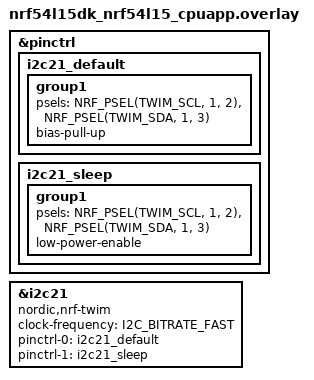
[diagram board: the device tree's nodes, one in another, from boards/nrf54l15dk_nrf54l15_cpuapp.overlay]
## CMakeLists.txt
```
# Smart-ring firmware for the Nordic nRF54L15 DK (cpuapp).
cmake_minimum_required(VERSION 3.20.0)

find_package(Zephyr REQUIRED HINTS $ENV{ZEPHYR_BASE})
project(smart_ring)

# Portable sensor-manager core, compiled unmodified into the app, plus its
# Zephyr port. SM_PORT_ZEPHYR selects the k_spinlock / k_uptime backing.
set(CORE_DIR ${CMAKE_CURRENT_SOURCE_DIR}/../../src)

target_sources(app PRIVATE
  src/main.c
  src/sensors.c
  src/ble.c
  ${CORE_DIR}/sensor_manager.c
  ${CORE_DIR}/sm_ringbuf.c
  ${CORE_DIR}/port/sm_port_zephyr.c
)

# ble_batch is only needed by the BLE notify path (enabled via ble.conf).
if(CONFIG_BT)
  target_sources(app PRIVATE ${CORE_DIR}/ble_batch.c)
endif()

target_include_directories(app PRIVATE ${CORE_DIR})
target_compile_definitions(app PRIVATE SM_PORT_ZEPHYR)
```

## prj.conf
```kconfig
# Smart-ring Zephyr app configuration.
CONFIG_PRINTK=y

# I2C sensor bus (TWIM21). The app uses the raw I2C API directly.
CONFIG_I2C=y
```

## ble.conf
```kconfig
# DK-only BLE build. Enables the Ring Data Service (src/ble.c) on top of the
# sensor pipeline. Uses upstream Zephyr's software Link-Layer controller, so it
# needs no nRF Connect SDK / SoftDevice blobs.
#
# Build with:
#   west build -b nrf54l15dk/nrf54l15/cpuapp . -- -DEXTRA_CONF_FILE=ble.conf
#
# Not runnable in LabWired: the nRF54L radio is not modelled.
CONFIG_BT=y
CONFIG_BT_PERIPHERAL=y
CONFIG_BT_DEVICE_NAME="SmartRing"
```

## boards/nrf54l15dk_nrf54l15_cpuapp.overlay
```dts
/*
 * Smart-ring sensor bus. The four sensors share TWIM21 (Zephyr node i2c21),
 * which is the instance LabWired's smart-ring system models as "twi21":
 *
 *   BMI270  IMU     0x68     MAX30102 PPG     0x57
 *   TMP117  temp    0x48     DRV2605  haptic  0x5A
 *
 * Addresses live in sensors.c (the app uses the raw I2C API against the bus
 * controller, not per-sensor drivers), so this overlay only has to bring the
 * bus up and give it pins.
 */

&pinctrl {
	i2c21_default: i2c21_default {
		group1 {
			psels = <NRF_PSEL(TWIM_SCL, 1, 2)>,
				<NRF_PSEL(TWIM_SDA, 1, 3)>;
			bias-pull-up;
		};
	};

	i2c21_sleep: i2c21_sleep {
		group1 {
			psels = <NRF_PSEL(TWIM_SCL, 1, 2)>,
				<NRF_PSEL(TWIM_SDA, 1, 3)>;
			low-power-enable;
		};
	};
};

&i2c21 {
	compatible = "nordic,nrf-twim";
	status = "okay";
	clock-frequency = <I2C_BITRATE_FAST>;
	pinctrl-0 = <&i2c21_default>;
	pinctrl-1 = <&i2c21_sleep>;
	pinctrl-names = "default", "sleep";
};
```

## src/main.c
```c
/*
 * main.c - smart-ring app entry point. Initialises the sensors and the
 * portable sensor-manager core, then runs the acquisition loop: a 20 ms timer
 * paces reads of the BMI270 (50 Hz) and TMP117 (1 Hz) into the manager, and
 * once a second the manager's pushed/dropped/buffered stats are printed.
 */
#include <zephyr/kernel.h>
#include <zephyr/version.h>

#include "sensors.h"
#include "sensor_manager.h"
#include "ble.h"

/* Acquisition tick. The IMU runs at 50 Hz, so one tick == one IMU period; the
 * manager's rate controllers derive the 1 Hz temperature cadence from it. */
#define TICK_PERIOD  K_MSEC(20)
#define STATS_PERIOD_US 1000000ULL

/* The timer only marks time; the blocking I2C reads happen in the loop below
 * (thread context), woken by this semaphore. */
static K_SEM_DEFINE(tick_sem, 0, 1);

static void tick_expiry(struct k_timer *timer)
{
	ARG_UNUSED(timer);
	k_sem_give(&tick_sem);
}

static K_TIMER_DEFINE(tick_timer, tick_expiry, NULL);

static void print_stats(sensor_manager_t *mgr)
{
	sm_stats_t s;

	sm_get_stats(mgr, &s);
	printk("stats: imu pushed=%u dropped=%u buffered=%u/%u missed=%u | "
	       "temp pushed=%u dropped=%u buffered=%u/%u missed=%u\n",
	       s.imu.pushed, s.imu.dropped, s.imu.count, s.imu.capacity,
	       s.imu_missed_deadlines, s.temp.pushed, s.temp.dropped, s.temp.count,
	       s.temp.capacity, s.temp_missed_deadlines);
}

int main(void)
{
	printk("\n=== smart-ring nRF54L15 (Zephyr %s) ===\n", KERNEL_VERSION_STRING);

	if (!sensors_init()) {
		printk("sensor bring-up failed; halting\n");
		return 0;
	}

	sensor_manager_t mgr;

	if (sm_init(&mgr, sm_time_now_us()) != SM_OK) {
		printk("sensor-manager init failed; halting\n");
		return 0;
	}

	ble_start(); /* advertises the Ring Data Service on the DK; no-op without CONFIG_BT */

	k_timer_start(&tick_timer, TICK_PERIOD, TICK_PERIOD);

	uint64_t last_stats_us = sm_time_now_us();

	for (;;) {
		k_sem_take(&tick_sem, K_FOREVER);

		uint64_t now_us = sm_time_now_us();

		if (sm_rate_poll(&mgr.imu_rate, now_us)) {
			int16_t accel[3], gyro[3];

			if (sensors_read_imu(accel, gyro) == 0) {
				sm_submit_imu(&mgr, accel, gyro, now_us);
			}
		}

		if (sm_rate_poll(&mgr.temp_rate, now_us)) {
			int32_t milli_celsius;

			if (sensors_read_temp(&milli_celsius) == 0) {
				sm_submit_temp(&mgr, milli_celsius, now_us);
			}
		}

		if (now_us - last_stats_us >= STATS_PERIOD_US) {
			print_stats(&mgr);
			ble_notify_imu(&mgr); /* drain a batch to the phone; no-op without CONFIG_BT */
			last_stats_us = now_us;
		}
	}

	return 0;
}
```

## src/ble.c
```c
/*
 * ble.c - Ring Data Service (IMU batch notifications). See ble.h.
 */
#include "ble.h"

#if defined(CONFIG_BT)

#include <zephyr/bluetooth/bluetooth.h>
#include <zephyr/bluetooth/conn.h>
#include <zephyr/bluetooth/gatt.h>
#include <zephyr/bluetooth/uuid.h>
#include <zephyr/kernel.h>

#include "ble_batch.h"
#include "sensor_manager.h"

/* Ring Data Service, random 128-bit base:
 *   service        7e9d0001-... , IMU-batch characteristic 7e9d0002-...
 */
#define RDS_UUID_SERVICE                                                                       \
	BT_UUID_128_ENCODE(0x7e9d0001, 0xc4b3, 0x4f2a, 0x9a10, 0x0011223344ff)
#define RDS_UUID_IMU_BATCH                                                                     \
	BT_UUID_128_ENCODE(0x7e9d0002, 0xc4b3, 0x4f2a, 0x9a10, 0x0011223344ff)

static const struct bt_uuid_128 rds_service = BT_UUID_INIT_128(RDS_UUID_SERVICE);
static const struct bt_uuid_128 rds_imu_batch = BT_UUID_INIT_128(RDS_UUID_IMU_BATCH);

static struct bt_conn *current_conn;
static bool notify_enabled;

static void imu_ccc_changed(const struct bt_gatt_attr *attr, uint16_t value)
{
	ARG_UNUSED(attr);
	notify_enabled = (value == BT_GATT_CCC_NOTIFY);
}

/* Notify-only characteristic: the phone subscribes, the ring pushes batches. */
BT_GATT_SERVICE_DEFINE(rds_svc,
	BT_GATT_PRIMARY_SERVICE(&rds_service),
	BT_GATT_CHARACTERISTIC(&rds_imu_batch.uuid, BT_GATT_CHRC_NOTIFY, BT_GATT_PERM_NONE,
			       NULL, NULL, NULL),
	BT_GATT_CCC(imu_ccc_changed, BT_GATT_PERM_READ | BT_GATT_PERM_WRITE));

/* The notify attribute is the characteristic value, index 2 in the table. */
#define IMU_VALUE_ATTR (&rds_svc.attrs[2])

static const struct bt_data adv[] = {
	BT_DATA_BYTES(BT_DATA_FLAGS, BT_LE_AD_GENERAL | BT_LE_AD_NO_BREDR),
	BT_DATA(BT_DATA_NAME_COMPLETE, CONFIG_BT_DEVICE_NAME, sizeof(CONFIG_BT_DEVICE_NAME) - 1),
};

static void connected(struct bt_conn *conn, uint8_t err)
{
	if (err == 0) {
		current_conn = bt_conn_ref(conn);
	}
	printk("ble: connected (err %u)\n", err);
}

static void disconnected(struct bt_conn *conn, uint8_t reason)
{
	ARG_UNUSED(conn);
	notify_enabled = false;
	if (current_conn) {
		bt_conn_unref(current_conn);
		current_conn = NULL;
	}
	printk("ble: disconnected (reason %u)\n", reason);
}

BT_CONN_CB_DEFINE(conn_cb) = {
	.connected = connected,
	.disconnected = disconnected,
};

int ble_start(void)
{
	int err = bt_enable(NULL);

	if (err) {
		printk("ble: bt_enable failed (%d)\n", err);
		return err;
	}
	err = bt_le_adv_start(BT_LE_ADV_CONN_FAST_1, adv, ARRAY_SIZE(adv), NULL, 0);
	if (err) {
		printk("ble: adv start failed (%d)\n", err);
	}
	return err;
}

void ble_notify_imu(sensor_manager_t *mgr)
{
	if (!current_conn || !notify_enabled) {
		return;
	}

	sm_imu_sample_t samples[BLE_IMU_MAX_RECORDS(BLE_DEFAULT_PAYLOAD)];
	size_t n = sm_peek_imu(mgr, samples, ARRAY_SIZE(samples));

	if (n == 0) {
		return;
	}

	sm_stats_t stats;

	sm_get_stats(mgr, &stats);

	uint8_t frame[BLE_DEFAULT_PAYLOAD];
	size_t consumed = 0;
	size_t len =
		ble_batch_encode_imu(samples, n, stats.imu.dropped, frame, sizeof(frame), &consumed);

	if (len > 0 && bt_gatt_notify(current_conn, IMU_VALUE_ATTR, frame, len) == 0) {
		sm_release_imu(mgr, consumed);
	}
}

#else /* !CONFIG_BT: inert stubs so main.c needs no #ifdefs. */

int ble_start(void)
{
	return 0;
}

void ble_notify_imu(sensor_manager_t *mgr)
{
	(void)mgr;
}

#endif /* CONFIG_BT */
```

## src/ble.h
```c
/*
 * ble.h - Ring Data Service: a minimal BLE peripheral that streams IMU batches.
 *
 * Built only when CONFIG_BT is enabled (see ble.conf); otherwise the two
 * entry points below compile to no-ops so main.c needs no #ifdefs. BLE is a
 * DK-only feature: LabWired does not model the nRF54L radio, so this path is
 * exercised on real silicon, not in the simulator.
 */
#ifndef BLE_H
#define BLE_H

#include "sensor_manager.h"

/* Start advertising the Ring Data Service. No-op (returns 0) without CONFIG_BT. */
int ble_start(void);

/*
 * Drain pending IMU samples from the manager into one GATT notification,
 * encoded with ble_batch_encode_imu. Does nothing if no central is connected
 * or nothing is buffered. No-op without CONFIG_BT.
 */
void ble_notify_imu(sensor_manager_t *mgr);

#endif /* BLE_H */
```

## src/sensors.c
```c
/*
 * sensors.c - raw-I2C access to the smart-ring sensor bus (TWIM21 / i2c21).
 */
#include "sensors.h"

#include <zephyr/device.h>
#include <zephyr/drivers/i2c.h>
#include <zephyr/kernel.h>

/* 7-bit bus addresses (see the board overlay for the bus topology). */
#define ADDR_IMU    0x68 /* BMI270  */
#define ADDR_PPG    0x57 /* MAX30102 */
#define ADDR_TEMP   0x48 /* TMP117  */
#define ADDR_HAPTIC 0x5A /* DRV2605 */

/* BMI270: CHIP_ID register and its fixed value; 6-axis data burst. */
#define BMI270_REG_CHIP_ID 0x00
#define BMI270_CHIP_ID     0x24
#define BMI270_REG_PWR_CTRL 0x7D
#define BMI270_PWR_ACC_GYR  0x0E /* enable accel + gyro (+ temp) */
#define BMI270_REG_ACC_DATA 0x0C /* accel[3] then gyro[3], 12 LE bytes */
#define BMI270_DATA_LEN     12

/* TMP117: DEVICE_ID (0x0117) and the temperature result register. */
#define TMP117_REG_TEMP      0x00
#define TMP117_REG_DEVICE_ID 0x0F
#define TMP117_DEVICE_ID     0x0117
/* 7.8125 m°C per LSB == 125/16 mC. */
#define TMP117_MC_NUM 125
#define TMP117_MC_DEN 16

/* MAX30102: PART_ID register and value (PPG, probed only). */
#define MAX30102_REG_PART_ID 0xFF
#define MAX30102_PART_ID     0x15

/* DRV2605: STATUS register; the top 3 bits carry the device ID (7). */
#define DRV2605_REG_STATUS    0x00
#define DRV2605_DEVICE_ID     7
#define DRV2605_ID_SHIFT      5

static const struct device *const i2c_bus = DEVICE_DT_GET(DT_NODELABEL(i2c21));

/* Read a big-endian 16-bit register (TMP117 layout: MSB first). */
static int read_reg16_be(uint8_t addr, uint8_t reg, uint16_t *out)
{
	uint8_t buf[2];
	int rc = i2c_burst_read(i2c_bus, addr, reg, buf, sizeof(buf));

	if (rc == 0) {
		*out = ((uint16_t)buf[0] << 8) | buf[1];
	}
	return rc;
}

bool sensors_init(void)
{
	if (!device_is_ready(i2c_bus)) {
		printk("i2c bus not ready\n");
		return false;
	}

	uint8_t chip_id = 0, part_id = 0, status = 0;
	uint16_t device_id = 0;
	bool imu_ok, temp_ok, ppg_ok, haptic_ok;

	imu_ok = i2c_reg_read_byte(i2c_bus, ADDR_IMU, BMI270_REG_CHIP_ID, &chip_id) == 0 &&
		 chip_id == BMI270_CHIP_ID;
	temp_ok = read_reg16_be(ADDR_TEMP, TMP117_REG_DEVICE_ID, &device_id) == 0 &&
		  device_id == TMP117_DEVICE_ID;
	ppg_ok = i2c_reg_read_byte(i2c_bus, ADDR_PPG, MAX30102_REG_PART_ID, &part_id) == 0 &&
		 part_id == MAX30102_PART_ID;
	haptic_ok = i2c_reg_read_byte(i2c_bus, ADDR_HAPTIC, DRV2605_REG_STATUS, &status) == 0 &&
		    (status >> DRV2605_ID_SHIFT) == DRV2605_DEVICE_ID;

	printk("probe: imu(bmi270) id=0x%02x %s\n", chip_id, imu_ok ? "OK" : "FAIL");
	printk("probe: temp(tmp117) id=0x%04x %s\n", device_id, temp_ok ? "OK" : "FAIL");
	printk("probe: ppg(max30102) id=0x%02x %s\n", part_id, ppg_ok ? "OK" : "FAIL");
	printk("probe: haptic(drv2605) id=%u %s\n", status >> DRV2605_ID_SHIFT,
	       haptic_ok ? "OK" : "FAIL");

	/*
	 * Power up the IMU's accel + gyro. A real BMI270 also needs its config
	 * blob uploaded here; that DK-only step is omitted deliberately (the
	 * data registers are all the pipeline reads).
	 */
	if (imu_ok) {
		i2c_reg_write_byte(i2c_bus, ADDR_IMU, BMI270_REG_PWR_CTRL, BMI270_PWR_ACC_GYR);
	}

	return imu_ok && temp_ok;
}

int sensors_read_imu(int16_t accel[3], int16_t gyro[3])
{
	uint8_t d[BMI270_DATA_LEN];
	int rc = i2c_burst_read(i2c_bus, ADDR_IMU, BMI270_REG_ACC_DATA, d, sizeof(d));

	if (rc != 0) {
		return rc;
	}
	for (int i = 0; i < 3; i++) {
		accel[i] = (int16_t)(d[2 * i] | (d[2 * i + 1] << 8));
		gyro[i] = (int16_t)(d[6 + 2 * i] | (d[6 + 2 * i + 1] << 8));
	}
	return 0;
}

int sensors_read_temp(int32_t *milli_celsius)
{
	uint16_t raw;
	int rc = read_reg16_be(ADDR_TEMP, TMP117_REG_TEMP, &raw);

	if (rc == 0) {
		*milli_celsius = (int32_t)(int16_t)raw * TMP117_MC_NUM / TMP117_MC_DEN;
	}
	return rc;
}
```

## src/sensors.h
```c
/*
 * sensors.h - thin driver over the four smart-ring I2C sensors, using the raw
 * Zephyr I2C API (no per-sensor driver bindings). The app only needs to probe
 * IDs once and then read the IMU and skin-temperature data streams.
 */
#ifndef SENSORS_H
#define SENSORS_H

#include <stdbool.h>
#include <stdint.h>

/*
 * Probe WHO_AM_I / ID on all four sensors and power up the IMU. Prints one
 * line per sensor. Returns true only if the two data-producing sensors
 * (BMI270 IMU + TMP117 temperature) both answered with the expected ID; the
 * PPG and haptic are probed for completeness but are not part of the pipeline.
 */
bool sensors_init(void);

/* Read the BMI270's 6-axis data (raw sensor LSB). Returns 0 on success. */
int sensors_read_imu(int16_t accel[3], int16_t gyro[3]);

/* Read the TMP117 skin temperature in milli-degrees Celsius. 0 on success. */
int sensors_read_temp(int32_t *milli_celsius);

#endif /* SENSORS_H */
```
